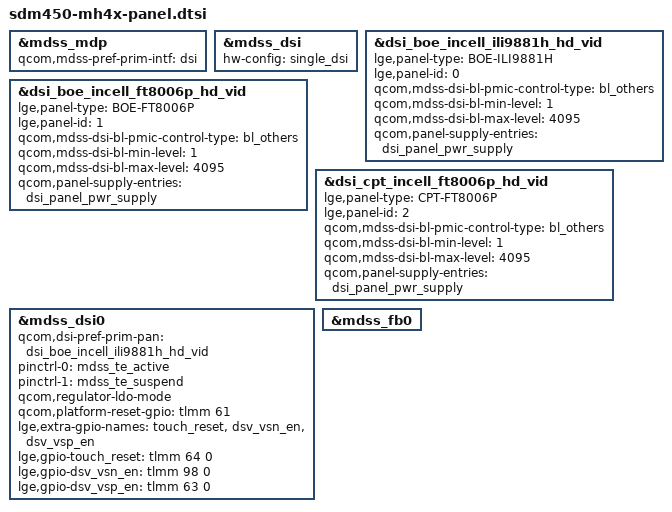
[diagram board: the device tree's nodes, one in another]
/*
 * Copyright (c) 2018, The Linux Foundation. All rights reserved.
 *
 * This program is free software; you can redistribute it and/or modify
 * it under the terms of the GNU General Public License version 2 and
 * only version 2 as published by the Free Software Foundation.
 *
 * This program is distributed in the hope that it will be useful,
 * but WITHOUT ANY WARRANTY; without even the implied warranty of
 * MERCHANTABILITY or FITNESS FOR A PARTICULAR PURPOSE.  See the
 * GNU General Public License for more details.
 */

#include "../sdm450-mh4x_common/sdm450-mh4x_common-panel.dtsi"

#include "../../../qcom/msm8953-mdss-panels.dtsi"

&mdss_mdp {
	qcom,mdss-pref-prim-intf = "dsi";
};

&mdss_dsi {
	hw-config = "single_dsi";
};

&dsi_boe_incell_ili9881h_hd_vid {
	lge,panel-type = "BOE-ILI9881H";
	lge,panel-id = <0>;
	qcom,mdss-dsi-bl-pmic-control-type = "bl_others";
	qcom,mdss-dsi-bl-min-level = <1>;
	qcom,mdss-dsi-bl-max-level = <4095>;
	qcom,panel-supply-entries = <&dsi_panel_pwr_supply>;
};

&dsi_boe_incell_ft8006p_hd_vid {
	lge,panel-type = "BOE-FT8006P";
	lge,panel-id = <1>;
	qcom,mdss-dsi-bl-pmic-control-type = "bl_others";
	qcom,mdss-dsi-bl-min-level = <1>;
	qcom,mdss-dsi-bl-max-level = <4095>;
	qcom,panel-supply-entries = <&dsi_panel_pwr_supply>;
};

&dsi_cpt_incell_ft8006p_hd_vid {
	lge,panel-type = "CPT-FT8006P";
	lge,panel-id = <2>;
	qcom,mdss-dsi-bl-pmic-control-type = "bl_others";
	qcom,mdss-dsi-bl-min-level = <1>;
	qcom,mdss-dsi-bl-max-level = <4095>;
	qcom,panel-supply-entries = <&dsi_panel_pwr_supply>;
};

&mdss_dsi0 {
	qcom,dsi-pref-prim-pan = <&dsi_boe_incell_ili9881h_hd_vid>;
	pinctrl-names = "mdss_default", "mdss_sleep";
	pinctrl-0 = <&mdss_te_active>;
	pinctrl-1 = <&mdss_te_suspend>;
	qcom,regulator-ldo-mode;

	qcom,platform-reset-gpio = <&tlmm 61 0>;

	lge,extra-gpio-names = "touch_reset", "dsv_vsn_en", "dsv_vsp_en";
	lge,gpio-touch_reset = <&tlmm 64 0>;
	lge,gpio-dsv_vsn_en = <&tlmm 98 0>;
	lge,gpio-dsv_vsp_en = <&tlmm 63 0>;
};
/*
&soc {
	dsi_panel_pwr_supply: dsi_panel_pwr_supply {
		#address-cells = <1>;
		#size-cells = <0>;

		qcom,panel-supply-entry@1 {
			reg = <1>;
			qcom,supply-name = "vddio";
			qcom,supply-min-voltage = <1800000>;
			qcom,supply-max-voltage = <1800000>;
			qcom,supply-enable-load = <100000>;
			qcom,supply-disable-load = <100>;
			qcom,supply-post-on-sleep = <1>;
		};
	};
};
*/
&mdss_fb0 {
	/delete-property/ qcom,mdss-fb-splash-logo-enabled;
};
